# SN32F100 register map
Vendor: SONiX Technology Co., Ltd.; Series: SN32F100; File version: 1.3
CPU: CM0 r0p0, little endian, no MPU, no FPU, 2 interrupt priority bits
Registers are 32-bit, read-write, reset 0x0 unless marked. A register's access mark holds for its fields unless they carry their own. Offsets are from the block's base; [hi:lo] are bit positions; {n}, {i} and the like mark numbered series.

## SN_UART0 — UART0
Base 0x40016000
Same registers: SN_UART1 0x40056000
0x00 RB ro — Offset:0x00 UARTn Receiver Buffer Register
  [7:0] RB — The oldest received byte in UART RX FIFO
0x00 TH wo (alternate view of RB) — Offset:0x00 UARTn Transmit Holding Register
  [7:0] TH — The oldest byte to be transmitted in UART TX FIFO when transmitter is available
0x00 DLL (alternate view of RB) — Offset:0x00 UARTn Divisor Latch LSB Register
  [7:0] DLL — DLL and DLM register determines the baud rate of UARTn
0x04 DLM — Offset:0x04 UARTn Divisor Latch MSB Register
  [7:0] DLM — DLL and DLM register determines the baud rate of UARTn
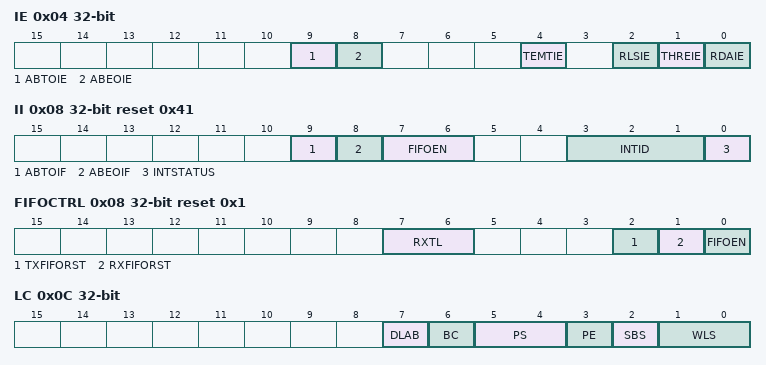
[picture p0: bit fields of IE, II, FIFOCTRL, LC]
0x04 IE (alternate view of DLM) — Offset:0x04 UARTn Interrupt Enable Register
  [9] ABTOIE — ABT0 interrupt enable
    0=Disable ABTO interrupt; 1=Enable ABTO interrupt
  [8] ABEOIE — ABE0 interrupt enable
    0=Disable ABEO interrupt; 1=Enable ABEO interrupt
  [4] TEMTIE — TEMT interrupt enable
    0=Disable TEMT interrupt; 1=Enable TEMT interrupt
  [2] RLSIE — RLS interrupt enable
    0=Disable RLS interrupt; 1=Enable RLS interrupt
  [1] THREIE — THRE interrupt enable
    0=Disable THRE interrupt; 1=Enable THRE interrupt
  [0] RDAIE — RDA interrupt enable
    0=Disable RDA interrupt; 1=Enable RDA interrupt
0x08 II ro reset 0x41 — Offset:0x08 UARTn Interrupt Identification Register
  [9] ABTOIF — ABTO interrupt flag
    0=Not Time-out (Auto-baud has not timed out); 1=Time-out (Auto-baud has timed out and interrupt is enabled)
  [8] ABEOIF — ABEO interrupt flag
    0=Not end (Auto-baud has not finished); 1=End (Auto-baud has finished and interrupt is enabled)
  [7:6] FIFOEN — Equal to FIFOEN bits in UARTn_FIFOCTRL register
  [3:1] INTID — Interrupt ID of RX FIFO
    1=3a (THRE interrupt); 2=2a (RDA (Receive Data Available)); 3=RLS (Receive Line Status); 6=2b (CTI (Character Time-out Indicator)); 7=3b (TEMT interrupt)
  [0] INTSTATUS — Interrupt status
    0=Pending (As least 1 interrupt is pending); 1=No interrupt
0x08 FIFOCTRL wo reset 0x1 — Offset:0x08 UARTn FIFO Control Register
  [7:6] RXTL — RX trigger level
    0=Trigger level 0 (1 character); 1=Trigger level 1 (4 character); 2=Trigger level 2 (8 character); 3=Trigger level 3 (14 character)
  [2] TXFIFORST — TX FIFO reset
    0=No impact; 1=Reset the pointer logic in TX FIFO
  [1] RXFIFORST — RX FIFO reset
    0=No impact; 1=Reset the pointer logic in RX FIFO
  [0] FIFOEN — FIFO enable
    0=No effect; 1=Enable FIFO
0x0C LC — Offset:0x0C UARTn Line Control Register
  [7] DLAB — Divisor Latch access
    0=Disable access to Divisor Latch; 1=Enable access to Divisor Latch
  [6] BC — Break control
    0=Disable break transmission; 1=Enable break transmission
  [5:4] PS — Parity selection
    0=Odd parity; 1=Even parity; 2=Forced 1 sticky parity; 3=Forced 0 sticky parity
  [3] PE — Parity enable
    0=Disable parity generation and checking; 1=Enable parity generation and checking
  [2] SBS — Stop bit selection
    0=1 stop bit; 1=2 stop bit (1.5 stop bit if WLS=0)
  [1:0] WLS — Word length selection
    {v}={v+5}-bit character (v=0..3)
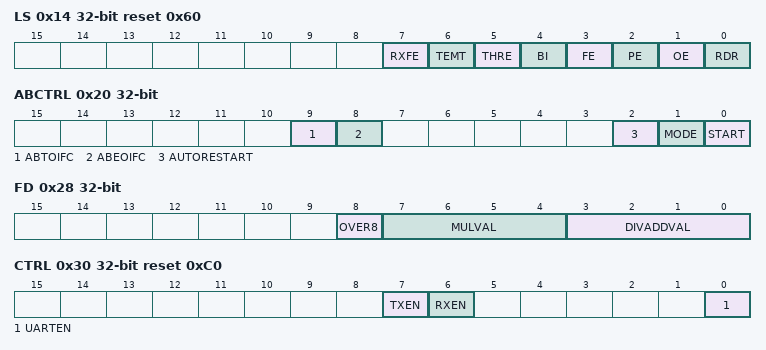
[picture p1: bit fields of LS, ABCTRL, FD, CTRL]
0x14 LS ro reset 0x60 — Offset:0x14 UARTn Line Status Register
  [7] RXFE — Receiver FIFO error flag
    0=No RX FIFO error (UARTn_RB contains no UART RX errors); 1=RX FIFO error (UARTn_RB contains at least 1 UART RX error)
  [6] TEMT — Transmitter empty flag
    0=Not empty (THR and/or TSR contains valid data); 1=Empty (THR and TSR are both empty)
  [5] THRE — THR empty flag
    0=Not empty (THR contains valid data); 1=Empty (THR (TX FIFO) is empty)
  [4] BI — Break interrupt flag
    0=No break interrupt; 1=Break interrupt status is active
  [3] FE — Framing error flag
    0=No framing error; 1=Framing error status is active
  [2] PE — Parity error flag
    0=No parity error; 1=Parity error status is active
  [1] OE — Overrun error flag
    0=No overrun error; 1=Overrun error status is active
  [0] RDR — Receiver data ready flag
    0=Not ready (UARTn_RB FIFO is empty); 1=Ready (UARTn_RB FIFO contains valid data)
0x1C SP — Offset:0x1C UARTn Scratch Pad Register
  [7:0] PAD — Pad informaton
0x20 ABCTRL — Offset:0x20 UARTn Auto-baud Control Register
  [9] ABTOIFC wo — Clear ABTOIF flag
    0=No effect; 1=Clear ABTOIF bit
  [8] ABEOIFC wo — Clear ABEOIF flag
    0=No effect; 1=Clear ABEOIF bit
  [2] AUTORESTART — Restart mode selection
    0=No restart; 1=Restart (Auto restart in case of timeout)
  [1] MODE — Auto-baud mode selection
    0=Mode 0 (Auto-baud mode 0); 1=Mode 1 (Auto-baud mode 1)
  [0] START — Auto-baud run bit
    0=Stop (Auto-baud is not running); 1=Start (Auto-baud ids running)
0x28 FD — Offset:0x28 UARTn Fractional Divider Register
  [8] OVER8 — Oversampling value
    0=Oversampling by 16; 1=Oversampling by 8
  [7:4] MULVAL — Baud rate generation prescaler multiplier value
    0=0000b (Baud rate prescaler multiplier value is 1); 1=0001b (Baud rate prescaler multiplier value is 2); 2=0010b (Baud rate prescaler multiplier value is 3); 3=0011b (Baud rate prescaler multiplier value is 4); 4=0100b (Baud rate prescaler multiplier value is 5); 5=0101b (Baud rate prescaler multiplier value is 6); 6=0110b (Baud rate prescaler multiplier value is 7); 7=0111b (Baud rate prescaler multiplier value is 8); 8=1000b (Baud rate prescaler multiplier value is 9); 9=1001b (Baud rate prescaler multiplier value is 10); 10=1010b (Baud rate prescaler multiplier value is 11); 11=1011b (Baud rate prescaler multiplier value is 12); 12=1100b (Baud rate prescaler multiplier value is 13); 13=1101b (Baud rate prescaler multiplier value is 14); 14=1110b (Baud rate prescaler multiplier value is 15); 15=1111b (Baud rate prescaler multiplier value is 16)
  [3:0] DIVADDVAL — Baud rate generation prescaler divisor value
0x30 CTRL reset 0xC0 — Offset:0x30 UARTn Control Register
  [7] TXEN — TX enable
    0=Disable TX; 1=Enable TX
  [6] RXEN — RX enable
    0=Disable RX; 1=Enable RX
  [0] UARTEN — UART enable
    0=Disable UART; 1=Enable UART
0x34 HDEN — Offset:0x34 UARTn Control Register
  [0] HDEN — Half-duplex mode enable
    0=Disable half-duplex mode; 1=Enable UART
